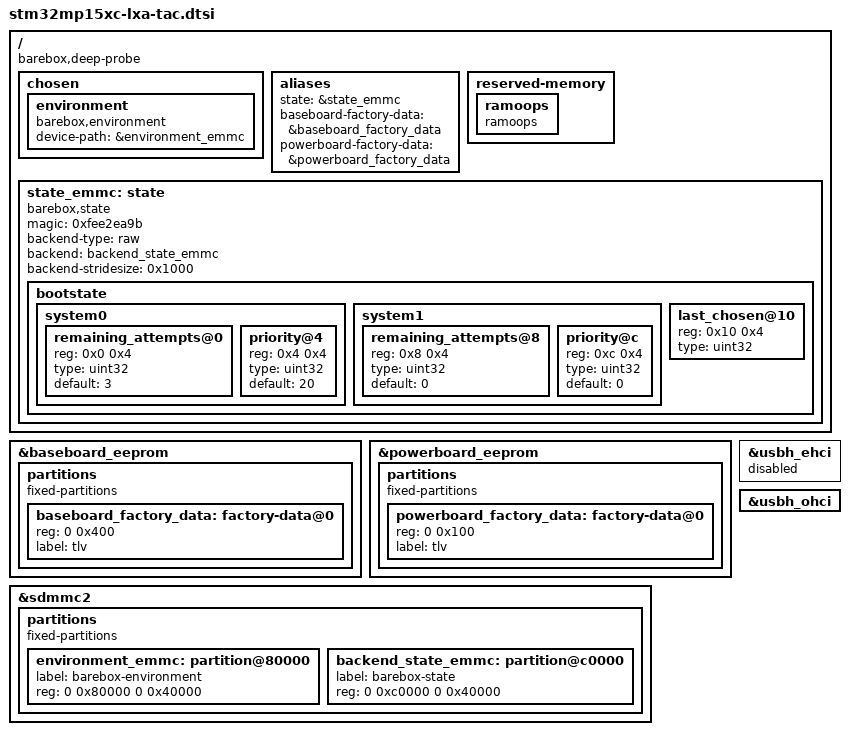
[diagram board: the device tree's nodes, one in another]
// SPDX-License-Identifier: (GPL-2.0+ OR BSD-3-Clause)
/*
 * Copyright (C) 2020 Ahmad Fatoum, Pengutronix
 */

#include "stm32mp151.dtsi"

/ {
	barebox,deep-probe;

	chosen {
		environment {
			compatible = "barebox,environment";
			device-path = &environment_emmc;
		};
	};

	aliases {
		state = &state_emmc;
		baseboard-factory-data = &baseboard_factory_data;
		powerboard-factory-data = &powerboard_factory_data;
	};

	reserved-memory {
		ramoops {
			compatible = "ramoops";
			/* Everything else will be fixed up at runtime */
		};
	};

	state_emmc: state {
		#address-cells = <1>;
		#size-cells = <1>;
		compatible = "barebox,state";
		magic = <0xfee2ea9b>;
		backend-type = "raw";
		backend = <&backend_state_emmc>;
		backend-stridesize = <0x1000>;

		bootstate {
			#address-cells = <1>;
			#size-cells = <1>;

			system0 {
				#address-cells = <1>;
				#size-cells = <1>;

				remaining_attempts@0 {
					reg = <0x0 0x4>;
					type = "uint32";
					default = <3>;
				};

				priority@4 {
					reg = <0x4 0x4>;
					type = "uint32";
					default = <20>;
				};
			};

			system1 {
				#address-cells = <1>;
				#size-cells = <1>;

				remaining_attempts@8 {
					reg = <0x8 0x4>;
					type = "uint32";
					default = <0>;
				};

				priority@c {
					reg = <0xc 0x4>;
					type = "uint32";
					default = <0>;
				};
			};

			last_chosen@10 {
				reg = <0x10 0x4>;
				type = "uint32";
			};
		};
	};
};

&baseboard_eeprom {
	partitions {
		compatible = "fixed-partitions";
		#address-cells = <1>;
		#size-cells = <1>;

		baseboard_factory_data: factory-data@0 {
			reg = <0 0x400>;
			label = "tlv";
		};
	};
};

&powerboard_eeprom {
	partitions {
		compatible = "fixed-partitions";
		#address-cells = <1>;
		#size-cells = <1>;

		powerboard_factory_data: factory-data@0 {
			reg = <0 0x100>;
			label = "tlv";
		};
	};
};

&sdmmc2 {
	partitions {
		compatible = "fixed-partitions";
		#address-cells = <2>;
		#size-cells = <2>;

		environment_emmc: partition@80000 {
			label = "barebox-environment";
			reg = <0 0x80000 0 0x40000>;
		};

		backend_state_emmc: partition@c0000 {
			label = "barebox-state";
			reg = <0 0xc0000 0 0x40000>;
		};
	};
};

&usbh_ehci {
	status = "disabled";
};

&usbh_ohci {
	status = "okay";
};
